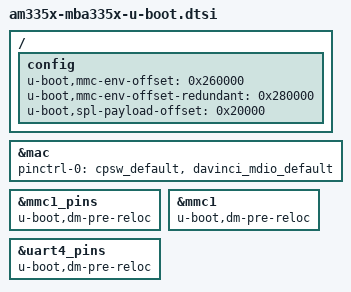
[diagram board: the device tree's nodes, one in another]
// SPDX-License-Identifier: GPL-2.0-only
/*
 * Copyright (c) 2022-2023 TQ-Systems GmbH <u-boot@ew.tq-group.com>,
 * D-82229 Seefeld, Germany.
 * Author: Markus Niebel
 */

#include "am335x-tqma335x-u-boot.dtsi"

/ {
	config {
		u-boot,mmc-env-offset = <0x260000>;
		u-boot,mmc-env-offset-redundant = <0x280000>;
		u-boot,spl-payload-offset = <0x20000>;
	};
};

&mac {
	/*
	 * U-Boot does not have a proper driver for the MDIO bus, so the
	 * pinctrl must be assigned to the Ethernet controller.
	 */
	pinctrl-0 = <&cpsw_default>, <&davinci_mdio_default>;
	/delete-property/ dual_emac;
};

&mmc1_pins {
	u-boot,dm-pre-reloc;
	u-boot,dm-spl;
};

&mmc1 {
	u-boot,dm-pre-reloc;
	u-boot,dm-spl;
};

&uart4_pins {
	u-boot,dm-pre-reloc;
	u-boot,dm-spl;
};
